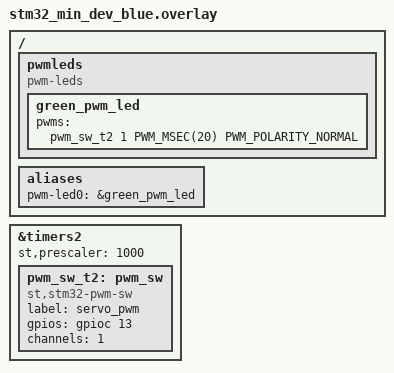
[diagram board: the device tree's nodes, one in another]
/*
 * SPDX-License-Identifier: Apache-2.0
 *
 * Copyright (c) 2022 STMicroelectronics
 */


/ {
	pwmleds: pwmleds {
		compatible = "pwm-leds";
		status = "okay";

		green_pwm_led: green_pwm_led {
			pwms = <&pwm_sw_t2 1 PWM_MSEC(20) PWM_POLARITY_NORMAL>;
		};
	};

    aliases {
        pwm-led0 = &green_pwm_led;
    };

};

&timers2 {
	st,prescaler = <1000>;
	status = "okay";

	pwm_sw_t2: pwm_sw {
		compatible = "st,stm32-pwm-sw";
		status = "okay";
		label = "servo_pwm";
		gpios = <&gpioc 13 GPIO_ACTIVE_HIGH>;
		channels = <1>;
		#pwm-cells = <3>;
	};
};
